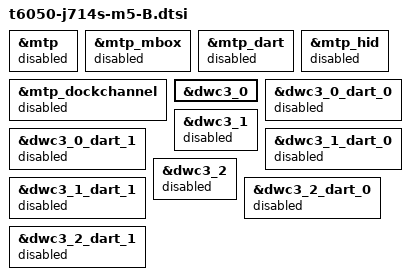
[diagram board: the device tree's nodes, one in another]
// SPDX-License-Identifier: GPL-2.0+ OR MIT
/*
 * m5-omarchy first-boot overrides for J714s, variant B (task 25): dwc3_0 without IOMMU. Included last by t6050-j714s.dts.
 * NATIVE gz5: SError right after the MTP DART probe returned (the next DART to probe was
 * dwc3_0_dart_0 @ 0x2a2f00000; the SError regs held x0 = 0x2a2f0000).
 */

/* 1. MTP (keyboard/trackpad over DockChannel) and its DART: off until DAPF is understood. */
&mtp { status = "disabled"; };
&mtp_mbox { status = "disabled"; };
&mtp_dart { status = "disabled"; };
&mtp_dockchannel { status = "disabled"; };
&mtp_hid { status = "disabled"; };

/* 2. dwc3_0 as gz5 had it (no power-domains), but its DARTs off and no iommus (DMA bypass), to test
 *    "SError = unpowered USB0 DART read". [HYPOTHESIS] dwc3 itself may still need power; the gadget may fail. */
&dwc3_0 { /delete-property/ iommus; };
&dwc3_0_dart_0 { status = "disabled"; };
&dwc3_0_dart_1 { status = "disabled"; };
&dwc3_1 { status = "disabled"; };
&dwc3_1_dart_0 { status = "disabled"; };
&dwc3_1_dart_1 { status = "disabled"; };
&dwc3_2 { status = "disabled"; };
&dwc3_2_dart_0 { status = "disabled"; };
&dwc3_2_dart_1 { status = "disabled"; };
